# HC32F120 register map
File version: 1.0
CPU: CM0+ r0p1, little endian, no MPU, no FPU, 2 interrupt priority bits
Registers are 32-bit, read-write, reset 0x0 unless marked. A register's access mark holds for its fields unless they carry their own. Offsets are from the block's base; [hi:lo] are bit positions; {n}, {i} and the like mark numbered series.

## ICG
Base 0x000000C0
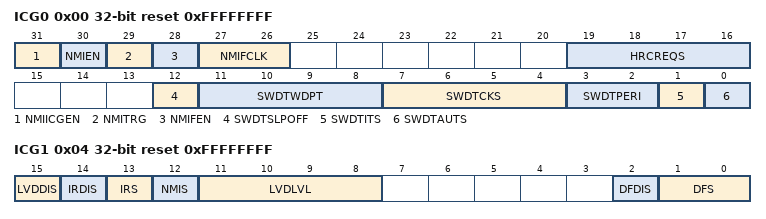
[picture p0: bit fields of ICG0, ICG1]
0x00 ICG0 ro reset 0xFFFFFFFF
  [31] NMIICGEN, [30] NMIEN, [29] NMITRG, [28] NMIFEN, [27:26] NMIFCLK, [19:16] HRCREQS, [12] SWDTSLPOFF, [11:8] SWDTWDPT, [7:4] SWDTCKS, [3:2] SWDTPERI, [1] SWDTITS, [0] SWDTAUTS
0x04 ICG1 ro reset 0xFFFFFFFF
  [15] LVDDIS, [14] IRDIS, [13] IRS, [12] NMIS, [11:8] LVDLVL, [2] DFDIS, [1:0] DFS
{0x0+4i} ICG{i} ro reset 0xFFFFFFFF (reset mask 0x0) (i=2..6)

## INTC
Base 0x40011000
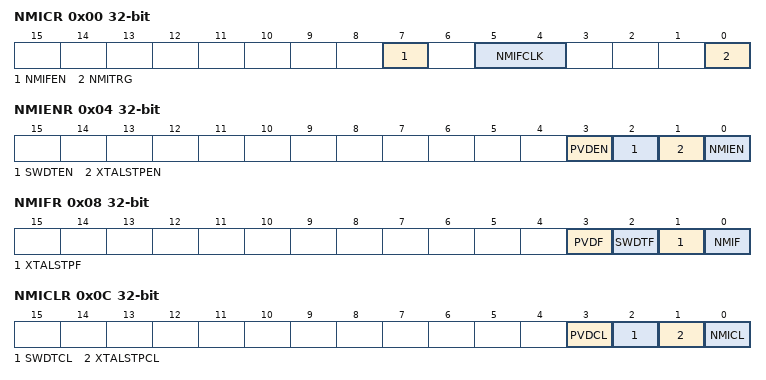
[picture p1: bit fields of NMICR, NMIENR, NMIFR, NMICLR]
0x00 NMICR
  [7] NMIFEN, [5:4] NMIFCLK, [0] NMITRG
0x04 NMIENR
  [3] PVDEN, [2] SWDTEN, [1] XTALSTPEN, [0] NMIEN
0x08 NMIFR ro
  [3] PVDF, [2] SWDTF, [1] XTALSTPF, [0] NMIF
0x0C NMICLR
  [3] PVDCL, [2] SWDTCL, [1] XTALSTPCL, [0] NMICL
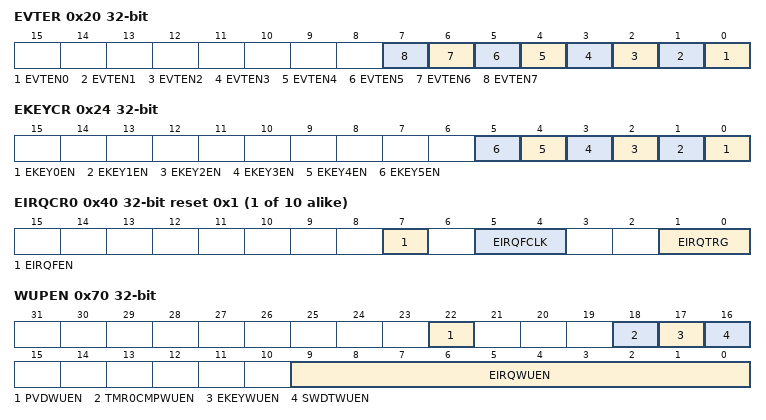
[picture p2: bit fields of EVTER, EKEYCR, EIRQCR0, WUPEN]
0x20 EVTER
  [n] EVTEN{n} (n=0..7)
0x24 EKEYCR
  [n] EKEY{n}EN (n=0..5)
0x3C FPRCR
  [7:0] FPRC
{0x40+4i} EIRQCR{i} reset 0x1 (i=0..9)
  [7] EIRQFEN, [5:4] EIRQFCLK, [1:0] EIRQTRG
0x70 WUPEN
  [22] PVDWUEN, [18] TMR0CMPWUEN, [17] EKEYWUEN, [16] SWDTWUEN, [9:0] EIRQWUEN
0x74 EIRQFR
  [9:0] EIRQF
0x78 EIRQCLR
  [9:0] EIRQCL
{0x80+4i} ISELAR{i} (i=8..23)
  [3:0] ISEL
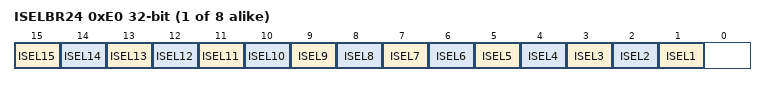
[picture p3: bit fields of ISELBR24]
{0x80+4i} ISELBR{i} (i=24..31)
  [n] ISEL{n} (n=1..15)

## PWC
Base 0x40014000
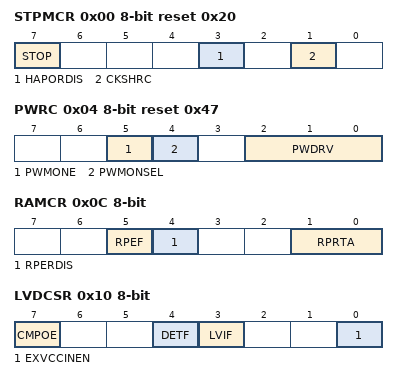
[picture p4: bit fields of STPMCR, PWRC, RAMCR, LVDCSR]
0x00 STPMCR 8-bit reset 0x20
  [7] STOP, [3] HAPORDIS, [1] CKSHRC
0x04 PWRC 8-bit reset 0x47
  [5] PWMONE, [4] PWMONSEL, [2:0] PWDRV
0x0C RAMCR 8-bit
  [5] RPEF, [4] RPERDIS, [1:0] RPRTA
0x10 LVDCSR 8-bit
  [7] CMPOE, [4] DETF, [3] LVIF ro, [0] EXVCCINEN
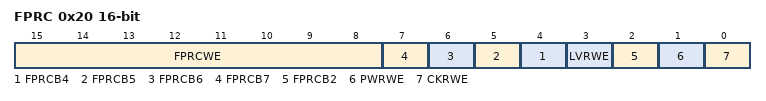
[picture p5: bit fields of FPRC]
0x20 FPRC 16-bit
  [15:8] FPRCWE wo, [n] FPRCB{n} (n=4..7), [3] LVRWE, [2] FPRCB2, [1] PWRWE, [0] CKRWE
0x40 DBGC 8-bit
  [0] DBGEN

## RMU
Base 0x40014100
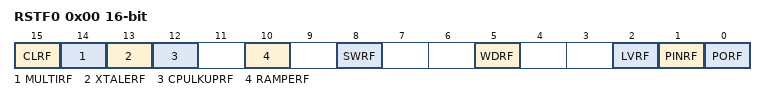
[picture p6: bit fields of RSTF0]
0x00 RSTF0 16-bit
  [15] CLRF, [14] MULTIRF, [13] XTALERF, [12] CPULKUPRF, [10] RAMPERF, [8] SWRF, [5] WDRF, [2] LVRF, [1] PINRF, [0] PORF

## SPI
Base 0x40003800
0x00 DR
  [15:0] SPD
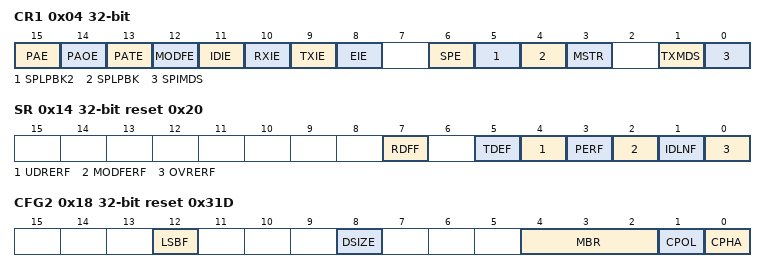
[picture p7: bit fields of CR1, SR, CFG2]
0x04 CR1
  [15] PAE, [14] PAOE, [13] PATE, [12] MODFE, [11] IDIE, [10] RXIE, [9] TXIE, [8] EIE, [6] SPE, [5] SPLPBK2, [4] SPLPBK, [3] MSTR, [1] TXMDS, [0] SPIMDS
0x0C CFG1 reset 0x10
  [8] SS0PV
0x14 SR reset 0x20
  [7] RDFF, [5] TDEF, [4] UDRERF, [3] PERF, [2] MODFERF, [1] IDLNF ro, [0] OVRERF
0x18 CFG2 reset 0x31D
  [12] LSBF, [8] DSIZE, [4:2] MBR, [1] CPOL, [0] CPHA

## SWDT
Base 0x4000CC00
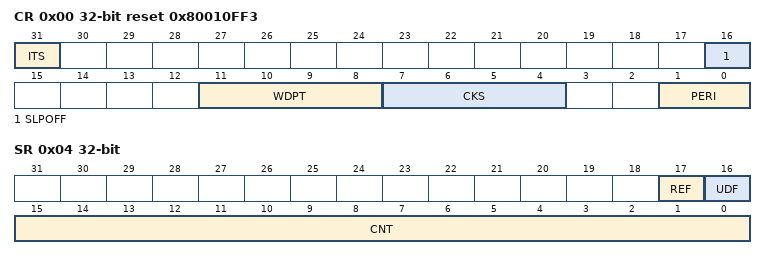
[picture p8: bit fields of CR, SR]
0x00 CR reset 0x80010FF3
  [31] ITS, [16] SLPOFF, [11:8] WDPT, [7:4] CKS, [1:0] PERI
0x04 SR
  [17] REF, [16] UDF, [15:0] CNT ro
0x08 RR
  [15:0] RF

## TMR0
Base 0x40005800
0x00 CNTAR
  [15:0] CNTA
0x08 CMPAR reset 0xFFFF
  [15:0] CMPA
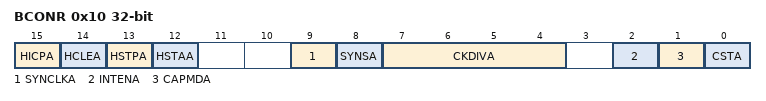
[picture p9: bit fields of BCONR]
0x10 BCONR
  [15] HICPA, [14] HCLEA, [13] HSTPA, [12] HSTAA, [9] SYNCLKA, [8] SYNSA, [7:4] CKDIVA, [2] INTENA, [1] CAPMDA, [0] CSTA
0x14 STFLR
  [0] CMFA

## TMRB1 — desc TMRB
Base 0x40007800
Same registers: TMRB2 0x40007C00, TMRB3 0x40008000, TMRB4 0x40008400, TMRB5 0x40008800, TMRB6 0x40008C00, TMRB7 0x40009000, TMRB8 0x40009400
0x00 CNTER 16-bit
  [15:0] CNT
0x04 PERAR 16-bit reset 0xFFFF
  [15:0] PER
0x40 CMPAR 16-bit reset 0xFFFF
  [15:0] CMP
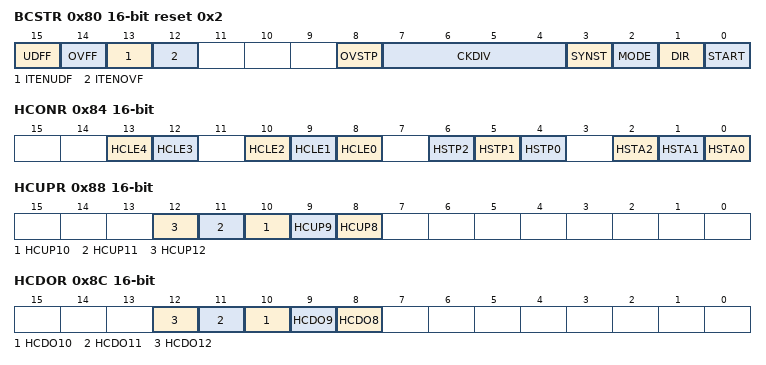
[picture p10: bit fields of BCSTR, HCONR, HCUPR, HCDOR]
0x80 BCSTR 16-bit reset 0x2
  [15] UDFF, [14] OVFF, [13] ITENUDF, [12] ITENOVF, [8] OVSTP, [7:4] CKDIV, [3] SYNST, [2] MODE, [1] DIR, [0] START
0x84 HCONR 16-bit
  [13] HCLE4, [12] HCLE3, [10] HCLE2, [9] HCLE1, [8] HCLE0, [6] HSTP2, [5] HSTP1, [4] HSTP0, [2] HSTA2, [1] HSTA1, [0] HSTA0
0x88 HCUPR 16-bit
  [n] HCUP{n} (n=8..12)
0x8C HCDOR 16-bit
  [n] HCDO{n} (n=8..12)
0x90 ICONR 16-bit
  [0] ITEN1
0x94 ECONR 16-bit
  [0] ETEN1
0x9C STFLR 16-bit
  [0] CMPF1
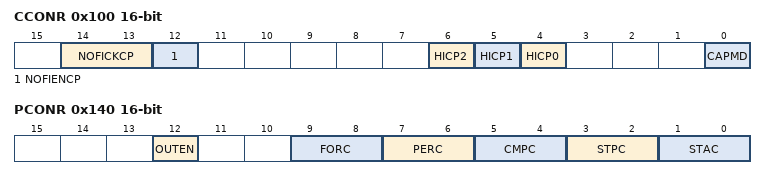
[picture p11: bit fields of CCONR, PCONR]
0x100 CCONR 16-bit
  [14:13] NOFICKCP, [12] NOFIENCP, [6] HICP2, [5] HICP1, [4] HICP0, [0] CAPMD
0x140 PCONR 16-bit
  [12] OUTEN, [9:8] FORC, [7:6] PERC, [5:4] CMPC, [3:2] STPC, [1:0] STAC

## USART1 — desc USART
Base 0x40001800
Same registers: USART2 0x40001C00, USART3 0x40002000, USART4 0x40002400
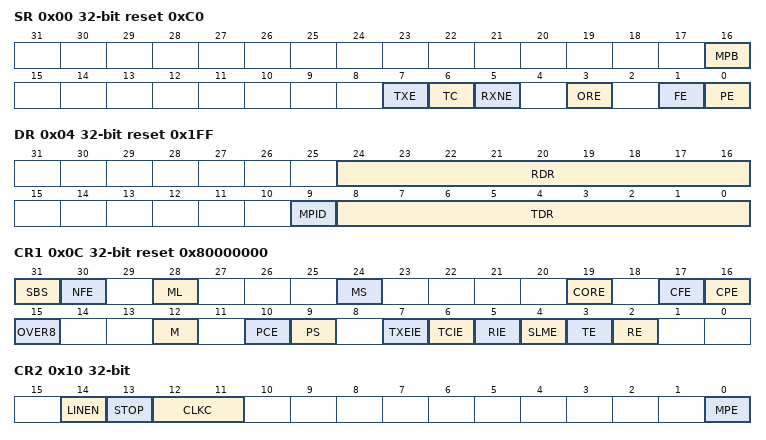
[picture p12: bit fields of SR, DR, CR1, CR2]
0x00 SR ro reset 0xC0
  [16] MPB, [7] TXE, [6] TC, [5] RXNE, [3] ORE, [1] FE, [0] PE
0x04 DR reset 0x1FF
  [24:16] RDR, [9] MPID, [8:0] TDR
0x08 BRR reset 0xFF00
  [15:8] DIV_INTEGER
0x0C CR1 reset 0x80000000
  [31] SBS, [30] NFE, [28] ML, [24] MS, [19] CORE wo, [17] CFE wo, [16] CPE wo, [15] OVER8, [12] M, [10] PCE, [9] PS, [7] TXEIE, [6] TCIE, [5] RIE, [4] SLME, [3] TE, [2] RE
0x10 CR2
  [14] LINEN, [13] STOP, [12:11] CLKC, [0] MPE
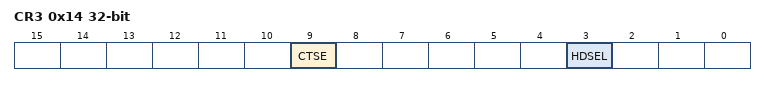
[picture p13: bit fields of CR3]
0x14 CR3
  [9] CTSE, [3] HDSEL
0x18 PR
  [1:0] PSC
